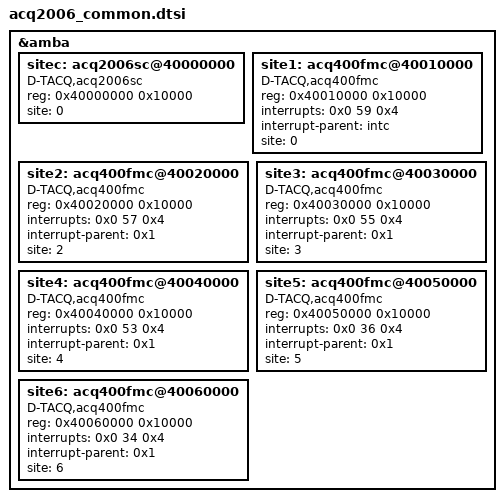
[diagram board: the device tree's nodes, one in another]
// SPDX-License-Identifier: GPL-2.0+
/*
 *   Copyright (C) 2013-2019 D-TACQ Solutions Ltd - http://www.d-tacq.com/
 *
 * This program is free software; you can redistribute it and/or modify
 * it under the terms of the GNU General Public License version 2 as
 * published by the Free Software Foundation.
 */

&amba {
	sitec: acq2006sc@40000000 {
		reg = <0x40000000 0x10000>;
		compatible = "D-TACQ,acq2006sc";
		site = <0>;
		/* potential sc interrupt .. not assigned for now 
		interrupts = <0x0 32 0x4>;
		interrupt-parent = <0x1>;			
		*/		
	};
	site1: acq400fmc@40010000 {
		compatible = "D-TACQ,acq400fmc";
		reg = <0x40010000 0x10000>;
		interrupts = <0x0 59 0x4>; 
		interrupt-parent = <&intc>;
		site = <0>;
	};
	site2: acq400fmc@40020000 {
		compatible = "D-TACQ,acq400fmc";
		reg = <0x40020000 0x10000>;
		interrupts = <0x0 57 0x4>;
		interrupt-parent = <0x1>;
		site = <2>;
	};
	site3: acq400fmc@40030000 {
		compatible = "D-TACQ,acq400fmc";
		reg = <0x40030000 0x10000>;
		interrupts = <0x0 55 0x4>;
		interrupt-parent = <0x1>;
		site = <3>;
	};
	site4: acq400fmc@40040000 {
		compatible = "D-TACQ,acq400fmc";
		reg = <0x40040000 0x10000>;
		interrupts = <0x0 53 0x4>; 
		interrupt-parent = <0x1>;
		site = <4>;
	};
	site5: acq400fmc@40050000 {
		compatible = "D-TACQ,acq400fmc";
		reg = <0x40050000 0x10000>;
		interrupts = <0x0 36 0x4>;
		interrupt-parent = <0x1>;
		site = <5>;
	};
	site6: acq400fmc@40060000 {
		compatible = "D-TACQ,acq400fmc";
		reg = <0x40060000 0x10000>;
		interrupts = <0x0 34 0x4>;
		interrupt-parent = <0x1>;
		site = <6>;
	};
};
